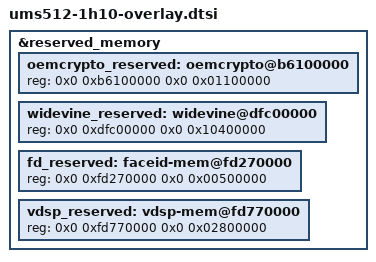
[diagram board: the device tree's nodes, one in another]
&reserved_memory {
	oemcrypto_reserved: oemcrypto@b6100000 {
		reg = <0x0 0xb6100000 0x0 0x01100000>;
	};
	widevine_reserved: widevine@dfc00000 {
		reg = <0x0 0xdfc00000 0x0 0x10400000>;
	};

	fd_reserved: faceid-mem@fd270000 {
		reg = <0x0 0xfd270000 0x0 0x00500000>;
	};

	vdsp_reserved: vdsp-mem@fd770000 {
		reg = <0x0 0xfd770000 0x0 0x02800000>;
	};
};
